# MIMXRT685S_cm33 register map
Vendor: nxp.com; File version: 1.0
CPU: CM33 r2p0, little endian, MPU, FPU, VTOR, 3 interrupt priority bits
Registers are 32-bit, read-write, reset 0x0 unless marked. A register's access mark holds for its fields unless they carry their own. Offsets are from the block's base; [hi:lo] are bit positions.

## CACHE64
Base 0x40033000
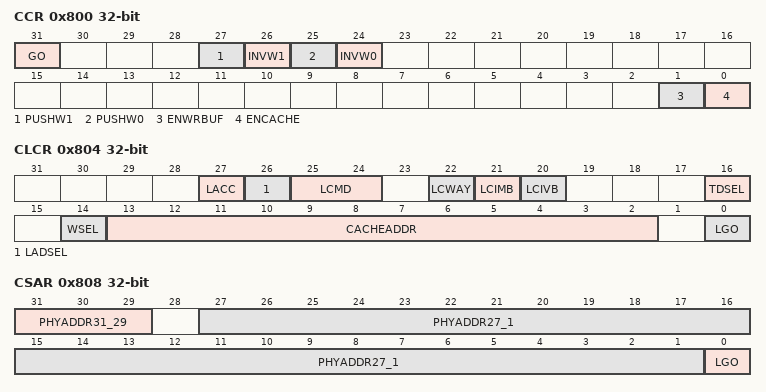
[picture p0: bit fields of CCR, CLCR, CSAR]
0x800 CCR — Cache control register
  [31] GO — Initiate Cache Command
    0=no_effect (Write: no effect. Read: no cache command active.); 1=init_cmd (Write: initiate command indicated by bits 27-24. Read: cache command active.)
  [27] PUSHW1 — Push Way 1
    0=no_operation; 1=pushw1 (When setting the GO bit, push all modified lines in way 1)
  [26] INVW1 — Invalidate Way 1
    0=no_operation; 1=invw1 (When setting the GO bit, invalidate all lines in way 1)
  [25] PUSHW0 — Push Way 0
    0=no_operation; 1=pushw0 (When setting the GO bit, push all modified lines in way 0)
  [24] INVW0 — Invalidate Way 0
    0=no_operation; 1=invw0 (When setting the GO bit, invalidate all lines in way 0.)
  [1] ENWRBUF — Enable Write Buffer
    0=disabled (Write buffer disabled); 1=enabled (Write buffer enabled)
  [0] ENCACHE — Cache enable
    0=disabled (Cache disabled); 1=enabled (Cache enabled)
0x804 CLCR — Cache line control register
  [27] LACC — Line access type
    0=read; 1=write
  [26] LADSEL — Line Address Select
    0=Cache address; 1=phys_addr (Physical address)
  [25:24] LCMD — Line Command
    0=search_rw (Search and read or write); 1=invalidate; 2=push; 3=clear
  [22] LCWAY — Line Command Way
  [21] LCIMB — Line Command Initial Modified Bit
  [20] LCIVB — Line Command Initial Valid Bit
  [16] TDSEL — Tag/Data Select
    0=data; 1=tag
  [14] WSEL — Way select
    0=way0; 1=way1
  [13:2] CACHEADDR — Cache address
  [0] LGO — Initiate Cache Line Command
    0=no_effect (Write: no effect. Read: no line command active.); 1=init_cmd (Write: initiate line command indicated by bits 27-24. Read: line command active.)
0x808 CSAR — Cache search address register
  [31:29] PHYADDR31_29 — Physical Address
  [27:1] PHYADDR27_1 — Physical Address
  [0] LGO — Initiate Cache Line Command
    0=no_effect (Write: no effect. Read: no line command active.); 1=init_cmd (Write: initiate line command indicated by bits CLCR[27:24]. Read: line command active.)
0x80C CCVR — Cache read/write value register
  [31:0] DATA — Cache read/write Data

## CACHE64_POLSEL
Base 0x40033000; alternate view of CACHE64
0x14 REG0_TOP reset 0x2AAA800 — Region 0 Top Boundary
  [26:10] REG0_TOP — Upper limit of Region 0
0x18 REG1_TOP reset 0x5555400 — Region 1 Top Boundary
  [26:10] REG1_TOP — Upper limit of Region 1
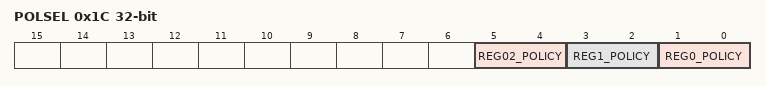
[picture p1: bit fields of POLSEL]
0x1C POLSEL — Policy Select
  [5:4] REG02_POLICY — Policy Select for Region 0
    0=REG2_00 (Non-cache); 1=REG2_01 (Write-thru); 2=REG2_10 (Write-back); 3=REG2_11 (Invalid)
  [3:2] REG1_POLICY — Policy Select for Region 0
    0=REG1_00 (Non-cache); 1=REG1_01 (Write-thru); 2=REG1_10 (Write-back); 3=REG1_11 (Invalid)
  [1:0] REG0_POLICY — Policy Select for Region 0
    0=REG0_00 (Non-cache); 1=REG0_01 (Write-thru); 2=REG0_10 (Write-back); 3=REG0_11 (Invalid)

## FLEXCOMM0 — LPC-Next0 Flexcomm serial communication
Base 0x40106000
Same registers: FLEXCOMM1 0x40107000, FLEXCOMM2 0x40108000, FLEXCOMM3 0x40109000, FLEXCOMM4 0x40122000, FLEXCOMM5 0x40123000, FLEXCOMM6 0x40124000, FLEXCOMM7 0x40125000, FLEXCOMM14 0x40126000, FLEXCOMM15 0x40127000
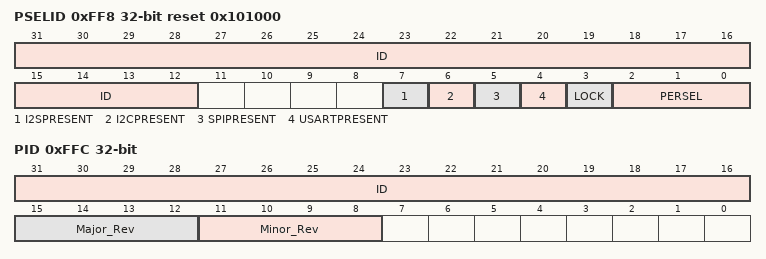
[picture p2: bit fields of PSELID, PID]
0xFF8 PSELID reset 0x101000 — Peripheral Select and Flexcomm ID register.
  [31:12] ID ro — Flexcomm ID.
  [7] I2SPRESENT ro — I 2S present indicator. This field is Read-only.
    0=NOT_PRESENT (This Flexcomm does not include the I2S function.); 1=PRESENT (This Flexcomm includes the I2S function.)
  [6] I2CPRESENT ro — I2C present indicator. This field is Read-only.
    0=NOT_PRESENT (This Flexcomm does not include the I2C function.); 1=PRESENT (This Flexcomm includes the I2C function.)
  [5] SPIPRESENT ro — SPI present indicator. This field is Read-only.
    0=NOT_PRESENT (This Flexcomm does not include the SPI function.); 1=PRESENT (This Flexcomm includes the SPI function.)
  [4] USARTPRESENT ro — USART present indicator. This field is Read-only.
    0=NOT_PRESENT (This Flexcomm does not include the USART function.); 1=PRESENT (This Flexcomm includes the USART function.)
  [3] LOCK — Lock the peripheral select. This field is writable by software.
    0=UNLOCKED (Peripheral select can be changed by software.); 1=LOCKED (Peripheral select is locked and cannot be changed until this Flexcomm or the entire device is reset.)
  [2:0] PERSEL — Peripheral Select. This field is writable by software.
    0=NO_PERIPH_SELECTED (No peripheral selected.); 1=USART (USART function selected.); 2=SPI (SPI function selected.); 3=I2C (I2C function selected.); 4=I2S_TRANSMIT (I2S transmit function selected.); 5=I2S_RECEIVE (I2S receive function selected.)
0xFFC PID — Peripheral identification register.
  [31:16] ID ro — Module identifier for the selected function.
  [15:12] Major_Rev ro — Major revision of module implementation.
  [11:8] Minor_Rev ro — Minor revision of module implementation.
